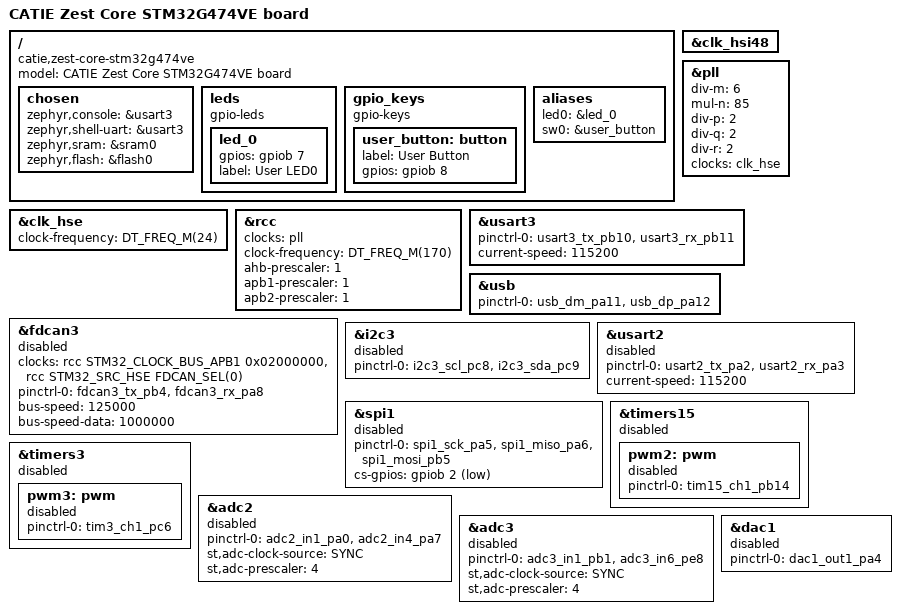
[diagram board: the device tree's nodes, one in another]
/*
 * Copyright (c) 2023 CATIE
 *
 * SPDX-License-Identifier: Apache-2.0
 */

/dts-v1/;
#include <st/g4/stm32g474Xe.dtsi>
#include <st/g4/stm32g474v(b-c-e)tx-pinctrl.dtsi>
#include "sixtron_connector.dtsi"

/ {
	model = "CATIE Zest Core STM32G474VE board";
	compatible = "catie,zest-core-stm32g474ve";

	chosen {
		zephyr,console = &usart3;
		zephyr,shell-uart = &usart3;
		zephyr,sram = &sram0;
		zephyr,flash = &flash0;
	};

	leds {
		compatible = "gpio-leds";
		led_0: led_0 {
			gpios = <&gpiob 7 GPIO_ACTIVE_HIGH>;
			label = "User LED0";
		};
	};

	gpio_keys {
		compatible = "gpio-keys";
		user_button: button {
			label = "User Button";
			gpios = <&gpiob 8 GPIO_ACTIVE_HIGH>;
		};
	};

	aliases {
		led0 = &led_0;
		sw0 = &user_button;
	};
};

// The Zest_Core_STM2G474VE has an external 24Mhz HSE oscillator available.
&clk_hse{
	status = "okay";
	clock-frequency = <DT_FREQ_M(24)>;
};

// For USB support, HSI48 need to be enable
&clk_hsi48 {
	status = "okay";
};

// For PLL supported values in Zephyr, see files :
// - dts\bindings\clock\st,stm32g4-pll-clock.yaml
// - dts\bindings\clock\st,stm32l4-pll-clock.yaml (include)

&pll {
	div-m = <6>;  // 24/6  = 4Mhz
	mul-n = <85>; // 4*85  = 340Mhz
	div-p = <2>;  // 340/2 = 170Mhz for PLLP
	div-q = <2>;  // 340/2 = 170Mhz for PLLQ
	div-r = <2>;  // 340/2 = 170Mhz for RCC
	clocks = <&clk_hse>;
	status = "okay";
};

&rcc {
	clocks = <&pll>;
	clock-frequency = <DT_FREQ_M(170)>;
	ahb-prescaler = <1>;
	apb1-prescaler = <1>;
	apb2-prescaler = <1>;
};

&usart3 {
	pinctrl-0 = <&usart3_tx_pb10 &usart3_rx_pb11>;
	pinctrl-names = "default";
	current-speed = <115200>;
	status = "okay";
};

// Enable the usb to get CDC ACM working (uart over USB)
zephyr_udc0: &usb {
	pinctrl-0 = <&usb_dm_pa11 &usb_dp_pa12>;
	pinctrl-names = "default";
	status = "okay";
};

// ========== 6tron BUS =============
// The following list all available zephyr supported modules using standard 6tron bus pin names.
// Be aware that these module are disabled by default, and need to be enable in your "app.overlay".

&fdcan3 {
	clocks = <&rcc STM32_CLOCK_BUS_APB1 0x02000000>,
			 <&rcc STM32_SRC_HSE FDCAN_SEL(0)>;
	pinctrl-0 = <&fdcan3_tx_pb4 &fdcan3_rx_pa8>;
	pinctrl-names = "default";
	bus-speed = <125000>;
	bus-speed-data = <1000000>;
	status = "disabled";
};

&i2c3 {
	pinctrl-0 = <&i2c3_scl_pc8 &i2c3_sda_pc9>;
	pinctrl-names = "default";
	status = "disabled";
};

&usart2 {
	pinctrl-0 = <&usart2_tx_pa2 &usart2_rx_pa3>;
	pinctrl-names = "default";
	current-speed = <115200>;
	status = "disabled";
};

&spi1 {
	pinctrl-0 = <&spi1_sck_pa5 &spi1_miso_pa6 &spi1_mosi_pb5>;
	pinctrl-names = "default";
	cs-gpios = <&gpiob 2 GPIO_ACTIVE_LOW>;
	status = "disabled";
};

//! pwm1 not supported on zest core stm32g474ve v1.0.0 !

&timers15 {
	status = "disabled";

	pwm2: pwm {
		pinctrl-0 = <&tim15_ch1_pb14>;
		pinctrl-names = "default";
		status = "disabled";
	};
};

&timers3 {
	status = "disabled";

	pwm3: pwm {
		pinctrl-0 = <&tim3_ch1_pc6>;
		pinctrl-names = "default";
		status = "disabled";
	};
};

&adc2 {
	pinctrl-0 = <&adc2_in1_pa0 &adc2_in4_pa7>;
	pinctrl-names = "default";
	st,adc-clock-source = <SYNC>;
	st,adc-prescaler = <4>;
	status = "disabled";
};

&adc3 {
	pinctrl-0 = <&adc3_in1_pb1 &adc3_in6_pe8>;
	pinctrl-names = "default";
	st,adc-clock-source = <SYNC>;
	st,adc-prescaler = <4>;
	status = "disabled";
};

&dac1 {
	pinctrl-0 = <&dac1_out1_pa4>;
	pinctrl-names = "default";
	status = "disabled";
};
